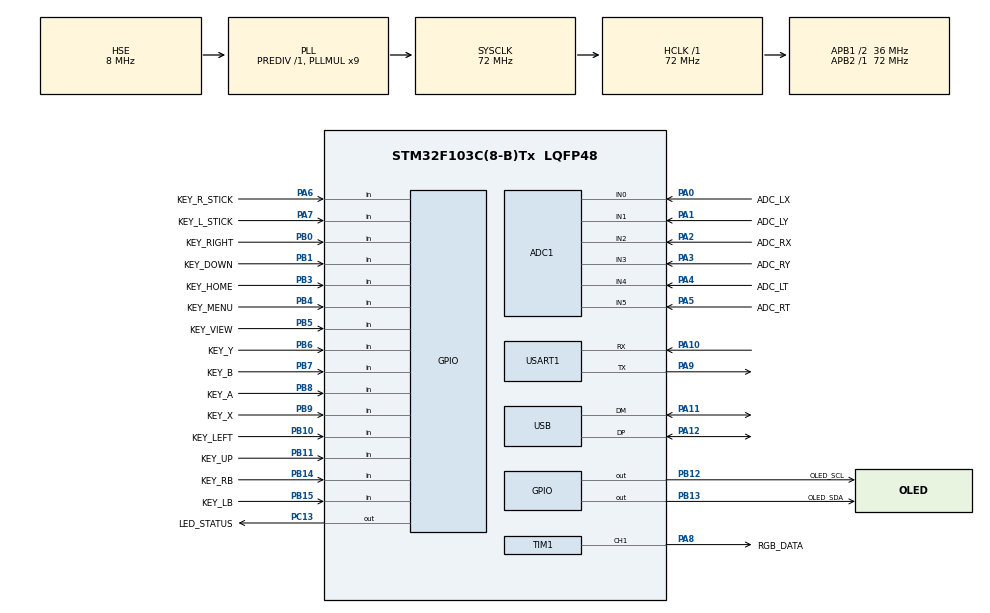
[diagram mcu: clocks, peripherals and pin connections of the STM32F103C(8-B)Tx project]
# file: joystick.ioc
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ADC1.Channel-0\#ChannelRegularConversion=ADC_CHANNEL_0
ADC1.Channel-1\#ChannelRegularConversion=ADC_CHANNEL_1
ADC1.Channel-2\#ChannelRegularConversion=ADC_CHANNEL_2
ADC1.Channel-3\#ChannelRegularConversion=ADC_CHANNEL_3
ADC1.Channel-4\#ChannelRegularConversion=ADC_CHANNEL_4
ADC1.Channel-5\#ChannelRegularConversion=ADC_CHANNEL_5
ADC1.ContinuousConvMode=ENABLE
ADC1.EnableAnalogWatchDog=false
ADC1.EnableInjectedConversion=DISABLE
ADC1.NbrOfConversion=6
ADC1.NbrOfConversionFlag=1
ADC1.Rank-0\#ChannelRegularConversion=1
ADC1.Rank-1\#ChannelRegularConversion=2
ADC1.Rank-2\#ChannelRegularConversion=3
ADC1.Rank-3\#ChannelRegularConversion=4
ADC1.Rank-4\#ChannelRegularConversion=5
ADC1.Rank-5\#ChannelRegularConversion=6
ADC1.SamplingTime-0\#ChannelRegularConversion=ADC_SAMPLETIME_55CYCLES_5
ADC1.SamplingTime-1\#ChannelRegularConversion=ADC_SAMPLETIME_55CYCLES_5
ADC1.SamplingTime-2\#ChannelRegularConversion=ADC_SAMPLETIME_55CYCLES_5
ADC1.SamplingTime-3\#ChannelRegularConversion=ADC_SAMPLETIME_55CYCLES_5
ADC1.SamplingTime-4\#ChannelRegularConversion=ADC_SAMPLETIME_55CYCLES_5
ADC1.SamplingTime-5\#ChannelRegularConversion=ADC_SAMPLETIME_55CYCLES_5
ADC1.master=1
Dma.ADC1.0.Direction=DMA_PERIPH_TO_MEMORY
Dma.ADC1.0.Instance=DMA1_Channel1
Dma.ADC1.0.MemDataAlignment=DMA_MDATAALIGN_HALFWORD
Dma.ADC1.0.MemInc=DMA_MINC_ENABLE
Dma.ADC1.0.Mode=DMA_CIRCULAR
Dma.ADC1.0.PeriphDataAlignment=DMA_PDATAALIGN_HALFWORD
Dma.ADC1.0.PeriphInc=DMA_PINC_DISABLE
Dma.ADC1.0.Priority=DMA_PRIORITY_HIGH
Dma.Request0=ADC1
Dma.Request1=USART1_RX
Dma.Request2=USART1_TX
Dma.USART1_RX.1.Direction=DMA_PERIPH_TO_MEMORY
Dma.USART1_RX.1.Instance=DMA1_Channel5
Dma.USART1_RX.1.MemDataAlignment=DMA_MDATAALIGN_BYTE
Dma.USART1_RX.1.MemInc=DMA_MINC_ENABLE
Dma.USART1_RX.1.Mode=DMA_NORMAL
Dma.USART1_RX.1.PeriphDataAlignment=DMA_PDATAALIGN_BYTE
Dma.USART1_RX.1.PeriphInc=DMA_PINC_DISABLE
Dma.USART1_RX.1.Priority=DMA_PRIORITY_LOW
Dma.USART1_TX.2.Direction=DMA_MEMORY_TO_PERIPH
Dma.USART1_TX.2.Instance=DMA1_Channel4
Dma.USART1_TX.2.MemDataAlignment=DMA_MDATAALIGN_BYTE
Dma.USART1_TX.2.MemInc=DMA_MINC_ENABLE
Dma.USART1_TX.2.Mode=DMA_NORMAL
Dma.USART1_TX.2.PeriphDataAlignment=DMA_PDATAALIGN_BYTE
Dma.USART1_TX.2.PeriphInc=DMA_PINC_DISABLE
Dma.USART1_TX.2.Priority=DMA_PRIORITY_LOW
FREERTOS.Queues01=KeyEventQueue,16,4,1,Dynamic,NULL,NULL
FREERTOS.Tasks01=InputTask,32,128,StartDefaultTask,Default,NULL,Dynamic,NULL,NULL;UsbTask,24,128,StartTask03,Default,NULL,Dynamic,NULL,NULL;BluetoothTask,24,128,StartTask04,Default,NULL,Dynamic,NULL,NULL;OledTask,16,192,StartTask05,Default,NULL,Dynamic,NULL,NULL;RgbTask,8,128,StartTask06,Default,NULL,Dynamic,NULL,NULL
FREERTOS.configTOTAL_HEAP_SIZE=8192
Mcu.Family=STM32F1
Mcu.Name=STM32F103C(8-B)Tx
Mcu.Package=LQFP48
NVIC.DMA1_Channel1_IRQn=true\:5\:0\:false\:false\:true\:true\:false\:true\:true
NVIC.DMA1_Channel4_IRQn=true\:5\:0\:false\:false\:true\:true\:false\:true\:true
NVIC.DMA1_Channel5_IRQn=true\:5\:0\:false\:false\:true\:true\:false\:true\:true
NVIC.PriorityGroup=NVIC_PRIORITYGROUP_4
NVIC.TIM4_IRQn=true\:15\:0\:false\:false\:true\:false\:false\:true\:true
NVIC.TimeBase=TIM4_IRQn
NVIC.TimeBaseIP=TIM4
NVIC.USART1_IRQn=true\:5\:0\:false\:false\:true\:true\:false\:true\:true
NVIC.USB_LP_CAN1_RX0_IRQn=true\:5\:0\:false\:false\:true\:true\:false\:true\:true
PA0-WKUP.GPIO_Label=ADC_LX
PA0-WKUP.Signal=ADCx_IN0
PA1.GPIO_Label=ADC_LY
PA1.Signal=ADCx_IN1
PA10.Mode=Asynchronous
PA10.Signal=USART1_RX
PA11.Mode=Device
PA11.Signal=USB_DM
PA12.Mode=Device
PA12.Signal=USB_DP
PA13.Mode=Serial_Wire
PA13.Signal=SYS_JTMS-SWDIO
PA14.Mode=Serial_Wire
PA14.Signal=SYS_JTCK-SWCLK
PA2.GPIO_Label=ADC_RX
PA2.Signal=ADCx_IN2
PA3.GPIO_Label=ADC_RY
PA3.Signal=ADCx_IN3
PA4.GPIO_Label=ADC_LT
PA4.Signal=ADCx_IN4
PA5.GPIO_Label=ADC_RT
PA5.Signal=ADCx_IN5
PA6.GPIO_Label=KEY_R_STICK
PA6.GPIO_Mode=GPIO_MODE_INPUT
PA6.GPIO_PuPd=GPIO_PULLUP
PA6.Signal=GPIO_Input
PA7.GPIO_Label=KEY_L_STICK
PA7.GPIO_Mode=GPIO_MODE_INPUT
PA7.GPIO_PuPd=GPIO_PULLUP
PA7.Signal=GPIO_Input
PA8.GPIO_Label=RGB_DATA
PA8.Signal=S_TIM1_CH1
PA9.Mode=Asynchronous
PA9.Signal=USART1_TX
PB0.GPIO_Label=KEY_RIGHT
PB0.GPIO_Mode=GPIO_MODE_INPUT
PB0.GPIO_PuPd=GPIO_PULLUP
PB0.Signal=GPIO_Input
PB1.GPIO_Label=KEY_DOWN
PB1.GPIO_Mode=GPIO_MODE_INPUT
PB1.GPIO_PuPd=GPIO_PULLUP
PB1.Signal=GPIO_Input
PB10.GPIO_Label=KEY_LEFT
PB10.GPIO_Mode=GPIO_MODE_INPUT
PB10.GPIO_PuPd=GPIO_PULLUP
PB10.Signal=GPIO_Input
PB11.GPIO_Label=KEY_UP
PB11.GPIO_Mode=GPIO_MODE_INPUT
PB11.GPIO_PuPd=GPIO_PULLUP
PB11.Signal=GPIO_Input
PB12.GPIO_Label=OLED_SCL
PB12.GPIO_ModeDefaultOutputOD=GPIO_MODE_OUTPUT_OD
PB12.GPIO_PuPd=GPIO_NOPULL
PB12.Signal=GPIO_Output
PB13.GPIO_Label=OLED_SDA
PB13.GPIO_ModeDefaultOutputOD=GPIO_MODE_OUTPUT_OD
PB13.GPIO_PuPd=GPIO_NOPULL
PB13.Signal=GPIO_Output
PB14.GPIO_Label=KEY_RB
PB14.GPIO_Mode=GPIO_MODE_INPUT
PB14.GPIO_PuPd=GPIO_PULLUP
PB14.Signal=GPIO_Input
PB15.GPIO_Label=KEY_LB
PB15.GPIO_Mode=GPIO_MODE_INPUT
PB15.GPIO_PuPd=GPIO_PULLUP
PB15.Signal=GPIO_Input
PB3.GPIO_Label=KEY_HOME
PB3.GPIO_Mode=GPIO_MODE_INPUT
PB3.GPIO_PuPd=GPIO_PULLUP
PB3.Signal=GPIO_Input
PB4.GPIO_Label=KEY_MENU
PB4.GPIO_Mode=GPIO_MODE_INPUT
PB4.GPIO_PuPd=GPIO_PULLUP
PB4.Signal=GPIO_Input
PB5.GPIO_Label=KEY_VIEW
PB5.GPIO_Mode=GPIO_MODE_INPUT
PB5.GPIO_PuPd=GPIO_PULLUP
PB5.Signal=GPIO_Input
PB6.GPIO_Label=KEY_Y
PB6.GPIO_Mode=GPIO_MODE_INPUT
PB6.GPIO_PuPd=GPIO_PULLUP
PB6.Signal=GPIO_Input
PB7.GPIO_Label=KEY_B
PB7.GPIO_Mode=GPIO_MODE_INPUT
PB7.GPIO_PuPd=GPIO_PULLUP
PB7.Signal=GPIO_Input
PB8.GPIO_Label=KEY_A
PB8.GPIO_Mode=GPIO_MODE_INPUT
PB8.GPIO_PuPd=GPIO_PULLUP
PB8.Signal=GPIO_Input
PB9.GPIO_Label=KEY_X
PB9.GPIO_Mode=GPIO_MODE_INPUT
PB9.GPIO_PuPd=GPIO_PULLUP
PB9.Signal=GPIO_Input
PC13-TAMPER-RTC.GPIO_Label=LED_STATUS
PC13-TAMPER-RTC.GPIO_PuPd=GPIO_NOPULL
PC13-TAMPER-RTC.PinState=GPIO_PIN_SET
PC13-TAMPER-RTC.Signal=GPIO_Output
PD0-OSC_IN.Mode=HSE-External-Oscillator
PD0-OSC_IN.Signal=RCC_OSC_IN
PD1-OSC_OUT.Mode=HSE-External-Oscillator
PD1-OSC_OUT.Signal=RCC_OSC_OUT
ProjectManager.HeapSize=0x200
ProjectManager.StackSize=0x400
ProjectManager.TargetToolchain=MDK-ARM V5.32
RCC.ADCPresc=RCC_ADCPCLK2_DIV6
RCC.AHBFreq_Value=72000000
RCC.APB1CLKDivider=RCC_HCLK_DIV2
RCC.APB1Freq_Value=36000000
RCC.APB1TimFreq_Value=72000000
RCC.APB2Freq_Value=72000000
RCC.APB2TimFreq_Value=72000000
RCC.HCLKFreq_Value=72000000
RCC.PLLMUL=RCC_PLL_MUL9
RCC.PLLSourceVirtual=RCC_PLLSOURCE_HSE
RCC.SYSCLKFreq_VALUE=72000000
RCC.SYSCLKSource=RCC_SYSCLKSOURCE_PLLCLK
RCC.USBFreq_Value=48000000
RCC.USBPrescaler=RCC_USBCLKSOURCE_PLL_DIV1_5
SH.ADCx_IN0.0=ADC1_IN0,IN0
SH.ADCx_IN1.0=ADC1_IN1,IN1
SH.ADCx_IN2.0=ADC1_IN2,IN2
SH.ADCx_IN3.0=ADC1_IN3,IN3
SH.ADCx_IN4.0=ADC1_IN4,IN4
SH.ADCx_IN5.0=ADC1_IN5,IN5
SH.S_TIM1_CH1.0=TIM1_CH1,PWM Generation1 CH1
TIM1.Channel-PWM\ Generation1\ CH1=TIM_CHANNEL_1
TIM1.Period=89
USART1.VirtualMode=VM_ASYNC
USB_DEVICE.CLASS_NAME_FS=HID
USB_DEVICE.VirtualMode=Hid
USB_DEVICE.VirtualModeFS=Hid_FS
VP_FREERTOS_VS_CMSIS_V2.Mode=CMSIS_V2
VP_SYS_VS_tim4.Mode=TIM4
VP_TIM1_VS_ClockSourceINT.Mode=Internal
VP_USB_DEVICE_VS_USB_DEVICE_HID_FS.Mode=HID_FS
board=custom

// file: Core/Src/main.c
/* USER CODE BEGIN Header */
/**
  ******************************************************************************
  * @file           : main.c
  * @brief          : Main program body
  ******************************************************************************
  * @attention
  *
  * Copyright (c) 2026 STMicroelectronics.
  * All rights reserved.
  *
  * This software is licensed under terms that can be found in the LICENSE file
  * in the root directory of this software component.
  * If no LICENSE file comes with this software, it is provided AS-IS.
  *
  ******************************************************************************
  */
/* USER CODE END Header */
#include "main.h"
#include "cmsis_os.h"
#include "adc.h"
#include "dma.h"
#include "tim.h"
#include "usart.h"
#include "usb_device.h"
#include "gpio.h"

/* USER CODE BEGIN Includes */
#include "bsp_joystick.h"

/* USER CODE END Includes */

void SystemClock_Config(void);
void MX_FREERTOS_Init(void);

int main(void)
{

  /* MCU Configuration--------------------------------------------------------*/

  /* Reset of all peripherals, Initializes the Flash interface and the Systick. */
  HAL_Init();

  /* Configure the system clock */
  SystemClock_Config();

  /* Initialize all configured peripherals */
  MX_GPIO_Init();
  MX_DMA_Init();
  MX_ADC1_Init();
  MX_USART1_UART_Init();
  MX_TIM1_Init();
  /* USER CODE BEGIN 2 */

  /* 启动ADC校准和摇杆DMA循环采样 */
  if (Bsp_JoystickInit() == 0)
  {
    Error_Handler();
  }

  /* USER CODE END 2 */

  /* Init scheduler */
  osKernelInitialize();

  /* Call init function for freertos objects (in cmsis_os2.c) */
  MX_FREERTOS_Init();

  /* Start scheduler */
  osKernelStart();

  /* We should never get here as control is now taken by the scheduler */

  /* Infinite loop */
  while (1)
  {

  }
}

void SystemClock_Config(void)
{
  RCC_OscInitTypeDef RCC_OscInitStruct = {0};
  RCC_ClkInitTypeDef RCC_ClkInitStruct = {0};
  RCC_PeriphCLKInitTypeDef PeriphClkInit = {0};

  /** Initializes the RCC Oscillators according to the specified parameters
  * in the RCC_OscInitTypeDef structure.
  */
  RCC_OscInitStruct.OscillatorType = RCC_OSCILLATORTYPE_HSE;
  RCC_OscInitStruct.HSEState = RCC_HSE_ON;
  RCC_OscInitStruct.HSEPredivValue = RCC_HSE_PREDIV_DIV1;
  RCC_OscInitStruct.HSIState = RCC_HSI_ON;
  RCC_OscInitStruct.PLL.PLLState = RCC_PLL_ON;
  RCC_OscInitStruct.PLL.PLLSource = RCC_PLLSOURCE_HSE;
  RCC_OscInitStruct.PLL.PLLMUL = RCC_PLL_MUL9;
  if (HAL_RCC_OscConfig(&RCC_OscInitStruct) != HAL_OK)
  {
    Error_Handler();
  }

  /** Initializes the CPU, AHB and APB buses clocks
  */
  RCC_ClkInitStruct.ClockType = RCC_CLOCKTYPE_HCLK|RCC_CLOCKTYPE_SYSCLK
                              |RCC_CLOCKTYPE_PCLK1|RCC_CLOCKTYPE_PCLK2;
  RCC_ClkInitStruct.SYSCLKSource = RCC_SYSCLKSOURCE_PLLCLK;
  RCC_ClkInitStruct.AHBCLKDivider = RCC_SYSCLK_DIV1;
  RCC_ClkInitStruct.APB1CLKDivider = RCC_HCLK_DIV2;
  RCC_ClkInitStruct.APB2CLKDivider = RCC_HCLK_DIV1;

  if (HAL_RCC_ClockConfig(&RCC_ClkInitStruct, FLASH_LATENCY_2) != HAL_OK)
  {
    Error_Handler();
  }
  PeriphClkInit.PeriphClockSelection = RCC_PERIPHCLK_ADC|RCC_PERIPHCLK_USB;
  PeriphClkInit.AdcClockSelection = RCC_ADCPCLK2_DIV6;
  PeriphClkInit.UsbClockSelection = RCC_USBCLKSOURCE_PLL_DIV1_5;
  if (HAL_RCCEx_PeriphCLKConfig(&PeriphClkInit) != HAL_OK)
  {
    Error_Handler();
  }
}

void HAL_TIM_PeriodElapsedCallback(TIM_HandleTypeDef *htim)
{
  if (htim->Instance == TIM4) {
    HAL_IncTick();
  }
}

void Error_Handler(void)
{
  __disable_irq();
  while (1)
  {
  }
}

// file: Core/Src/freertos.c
/* USER CODE BEGIN Header */
/**
  ******************************************************************************
  * File Name          : freertos.c
  * Description        : Code for freertos applications
  ******************************************************************************
  * @attention
  *
  * Copyright (c) 2026 STMicroelectronics.
  * All rights reserved.
  *
  * This software is licensed under terms that can be found in the LICENSE file
  * in the root directory of this software component.
  * If no LICENSE file comes with this software, it is provided AS-IS.
  *
  ******************************************************************************
  */
/* USER CODE END Header */

#include "FreeRTOS.h"
#include "task.h"
#include "main.h"
#include "cmsis_os.h"

/* USER CODE BEGIN Includes */
#include "app_input.h"
#include "app_tasks.h"

/* USER CODE END Includes */

/* Definitions for InputTask */
osThreadId_t InputTaskHandle;
const osThreadAttr_t InputTask_attributes = {
  .name = "InputTask",
  .stack_size = 128 * 4,
  .priority = (osPriority_t) osPriorityAboveNormal,
};
/* Definitions for UsbTask */
osThreadId_t UsbTaskHandle;
const osThreadAttr_t UsbTask_attributes = {
  .name = "UsbTask",
  .stack_size = 128 * 4,
  .priority = (osPriority_t) osPriorityNormal,
};
/* Definitions for BluetoothTask */
osThreadId_t BluetoothTaskHandle;
const osThreadAttr_t BluetoothTask_attributes = {
  .name = "BluetoothTask",
  .stack_size = 128 * 4,
  .priority = (osPriority_t) osPriorityNormal,
};
/* Definitions for OledTask */
osThreadId_t OledTaskHandle;
const osThreadAttr_t OledTask_attributes = {
  .name = "OledTask",
  .stack_size = 192 * 4,
  .priority = (osPriority_t) osPriorityBelowNormal,
};
/* Definitions for RgbTask */
osThreadId_t RgbTaskHandle;
const osThreadAttr_t RgbTask_attributes = {
  .name = "RgbTask",
  .stack_size = 128 * 4,
  .priority = (osPriority_t) osPriorityLow,
};

void StartDefaultTask(void *argument);
void StartTask03(void *argument);
void StartTask04(void *argument);
void StartTask05(void *argument);
void StartTask06(void *argument);

extern void MX_USB_DEVICE_Init(void);
void MX_FREERTOS_Init(void); /* (MISRA C 2004 rule 8.1) */

void MX_FREERTOS_Init(void) {
  /* USER CODE BEGIN Init */

  if (App_TasksInit() == 0)
  {
    Error_Handler();
  }

  /* USER CODE END Init */

  /* Create the thread(s) */
  /* creation of InputTask */
  InputTaskHandle = osThreadNew(StartDefaultTask, NULL, &InputTask_attributes);

  /* creation of UsbTask */
  UsbTaskHandle = osThreadNew(StartTask03, NULL, &UsbTask_attributes);

  /* creation of BluetoothTask */
  BluetoothTaskHandle = osThreadNew(StartTask04, NULL, &BluetoothTask_attributes);

  /* creation of OledTask */
  OledTaskHandle = osThreadNew(StartTask05, NULL, &OledTask_attributes);

  /* creation of RgbTask */
  RgbTaskHandle = osThreadNew(StartTask06, NULL, &RgbTask_attributes);

}

void StartDefaultTask(void *argument)
{
  /* USER CODE BEGIN StartDefaultTask */
  App_InputTask(argument);
  /* USER CODE END StartDefaultTask */
  /* Infinite loop */
  for(;;)
  {
    osDelay(1);
  }
}

void StartTask03(void *argument)
{
  /* USER CODE BEGIN StartTask03 */
  App_UsbTask(argument);
  /* USER CODE END StartTask03 */
}

void StartTask04(void *argument)
{
  /* USER CODE BEGIN StartTask04 */
  App_BluetoothTask(argument);
  /* USER CODE END StartTask04 */
}

void StartTask05(void *argument)
{
  /* USER CODE BEGIN StartTask05 */
  App_OledTask(argument);
  /* USER CODE END StartTask05 */
  /* Infinite loop */
  for(;;)
  {
    osDelay(1);
  }
}

void StartTask06(void *argument)
{
  /* USER CODE BEGIN StartTask06 */
  App_RgbTask(argument);
  /* USER CODE END StartTask06 */
  /* Infinite loop */
  for(;;)
  {
    osDelay(1);
  }
}
